AUTOSAR XML (schema 4-0-3)
package /ComponentTypes
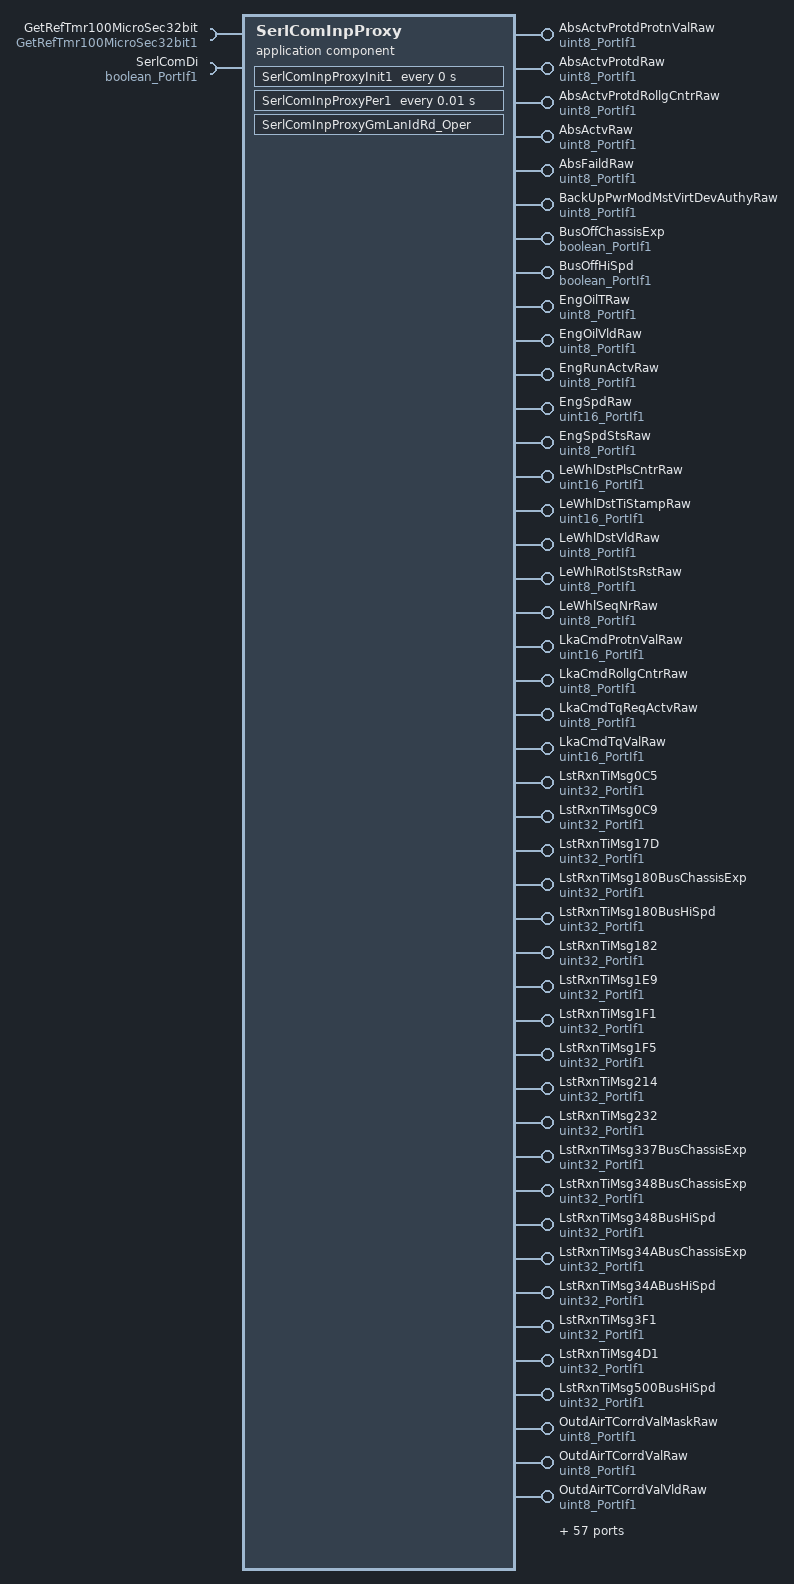
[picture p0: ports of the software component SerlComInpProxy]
  application sw component type SerlComInpProxy
    101 x provide port:
      AbsActvProtdProtnValRaw: nonqueued-sender-com-spec{data-element=Val, init-value=0}, provided-interface=uint8_PortIf1
      AbsActvProtdRaw: nonqueued-sender-com-spec{data-element=Val, init-value=0}, provided-interface=uint8_PortIf1
      AbsActvProtdRollgCntrRaw: nonqueued-sender-com-spec{data-element=Val, init-value=0}, provided-interface=uint8_PortIf1
      AbsActvRaw: nonqueued-sender-com-spec{data-element=Val, init-value=0}, provided-interface=uint8_PortIf1
      AbsFaildRaw: nonqueued-sender-com-spec{data-element=Val, init-value=0}, provided-interface=uint8_PortIf1
      BackUpPwrModMstVirtDevAuthyRaw: nonqueued-sender-com-spec{data-element=Val, init-value=0}, provided-interface=uint8_PortIf1
      BusOffChassisExp: nonqueued-sender-com-spec{data-element=Logl, init-value=0}, provided-interface=boolean_PortIf1
      BusOffHiSpd: nonqueued-sender-com-spec{data-element=Logl, init-value=0}, provided-interface=boolean_PortIf1
      EngOilTRaw: nonqueued-sender-com-spec{data-element=Val, init-value=0}, provided-interface=uint8_PortIf1
      EngOilVldRaw: nonqueued-sender-com-spec{data-element=Val, init-value=0}, provided-interface=uint8_PortIf1
      EngRunActvRaw: nonqueued-sender-com-spec{data-element=Val, init-value=0}, provided-interface=uint8_PortIf1
      EngSpdRaw: nonqueued-sender-com-spec{data-element=Val, init-value=0}, provided-interface=uint16_PortIf1
      EngSpdStsRaw: nonqueued-sender-com-spec{data-element=Val, init-value=0}, provided-interface=uint8_PortIf1
      LeWhlDstPlsCntrRaw: nonqueued-sender-com-spec{data-element=Val, init-value=0}, provided-interface=uint16_PortIf1
      LeWhlDstTiStampRaw: nonqueued-sender-com-spec{data-element=Val, init-value=0}, provided-interface=uint16_PortIf1
      LeWhlDstVldRaw: nonqueued-sender-com-spec{data-element=Val, init-value=0}, provided-interface=uint8_PortIf1
      LeWhlRotlStsRstRaw: nonqueued-sender-com-spec{data-element=Val, init-value=0}, provided-interface=uint8_PortIf1
      LeWhlSeqNrRaw: nonqueued-sender-com-spec{data-element=Val, init-value=0}, provided-interface=uint8_PortIf1
      LkaCmdProtnValRaw: nonqueued-sender-com-spec{data-element=Val, init-value=0}, provided-interface=uint16_PortIf1
      LkaCmdRollgCntrRaw: nonqueued-sender-com-spec{data-element=Val, init-value=0}, provided-interface=uint8_PortIf1
      LkaCmdTqReqActvRaw: nonqueued-sender-com-spec{data-element=Val, init-value=0}, provided-interface=uint8_PortIf1
      LkaCmdTqValRaw: nonqueued-sender-com-spec{data-element=Val, init-value=0}, provided-interface=uint16_PortIf1
      LstRxnTiMsg0C5: nonqueued-sender-com-spec{data-element=Val, init-value=0}, provided-interface=uint32_PortIf1
      LstRxnTiMsg0C9: nonqueued-sender-com-spec{data-element=Val, init-value=0}, provided-interface=uint32_PortIf1
      LstRxnTiMsg17D: nonqueued-sender-com-spec{data-element=Val, init-value=0}, provided-interface=uint32_PortIf1
      LstRxnTiMsg180BusChassisExp: nonqueued-sender-com-spec{data-element=Val, init-value=0}, provided-interface=uint32_PortIf1
      LstRxnTiMsg180BusHiSpd: nonqueued-sender-com-spec{data-element=Val, init-value=0}, provided-interface=uint32_PortIf1
      LstRxnTiMsg182: nonqueued-sender-com-spec{data-element=Val, init-value=0}, provided-interface=uint32_PortIf1
      LstRxnTiMsg1E9: nonqueued-sender-com-spec{data-element=Val, init-value=0}, provided-interface=uint32_PortIf1
      LstRxnTiMsg1F1: nonqueued-sender-com-spec{data-element=Val, init-value=0}, provided-interface=uint32_PortIf1
      LstRxnTiMsg1F5: nonqueued-sender-com-spec{data-element=Val, init-value=0}, provided-interface=uint32_PortIf1
      LstRxnTiMsg214: nonqueued-sender-com-spec{data-element=Val, init-value=0}, provided-interface=uint32_PortIf1
      LstRxnTiMsg232: nonqueued-sender-com-spec{data-element=Val, init-value=0}, provided-interface=uint32_PortIf1
      LstRxnTiMsg337BusChassisExp: nonqueued-sender-com-spec{data-element=Val, init-value=0}, provided-interface=uint32_PortIf1
      LstRxnTiMsg348BusChassisExp: nonqueued-sender-com-spec{data-element=Val, init-value=0}, provided-interface=uint32_PortIf1
      LstRxnTiMsg348BusHiSpd: nonqueued-sender-com-spec{data-element=Val, init-value=0}, provided-interface=uint32_PortIf1
      LstRxnTiMsg34ABusChassisExp: nonqueued-sender-com-spec{data-element=Val, init-value=0}, provided-interface=uint32_PortIf1
      LstRxnTiMsg34ABusHiSpd: nonqueued-sender-com-spec{data-element=Val, init-value=0}, provided-interface=uint32_PortIf1
      LstRxnTiMsg3F1: nonqueued-sender-com-spec{data-element=Val, init-value=0}, provided-interface=uint32_PortIf1
      LstRxnTiMsg4D1: nonqueued-sender-com-spec{data-element=Val, init-value=0}, provided-interface=uint32_PortIf1
      LstRxnTiMsg500BusHiSpd: nonqueued-sender-com-spec{data-element=Val, init-value=0}, provided-interface=uint32_PortIf1
      OutdAirTCorrdValMaskRaw: nonqueued-sender-com-spec{data-element=Val, init-value=0}, provided-interface=uint8_PortIf1
      OutdAirTCorrdValRaw: nonqueued-sender-com-spec{data-element=Val, init-value=0}, provided-interface=uint8_PortIf1
      OutdAirTCorrdValVldRaw: nonqueued-sender-com-spec{data-element=Val, init-value=0}, provided-interface=uint8_PortIf1
      PtCrkActvRaw: nonqueued-sender-com-spec{data-element=Val, init-value=0}, provided-interface=uint8_PortIf1
      RdntVehStabyEnhmtSysActvRaw: nonqueued-sender-com-spec{data-element=Val, init-value=0}, provided-interface=uint8_PortIf1
      RdntVehStabyEnhmtSysActvRollgCntrRaw: nonqueued-sender-com-spec{data-element=Val, init-value=0}, provided-interface=uint8_PortIf1
      RiWhlDstPlsCntrRaw: nonqueued-sender-com-spec{data-element=Val, init-value=0}, provided-interface=uint16_PortIf1
      RiWhlDstTiStampRaw: nonqueued-sender-com-spec{data-element=Val, init-value=0}, provided-interface=uint16_PortIf1
      RiWhlDstVldRaw: nonqueued-sender-com-spec{data-element=Val, init-value=0}, provided-interface=uint8_PortIf1
      RiWhlRotlStsRstRaw: nonqueued-sender-com-spec{data-element=Val, init-value=0}, provided-interface=uint8_PortIf1
      RiWhlSeqNrRaw: nonqueued-sender-com-spec{data-element=Val, init-value=0}, provided-interface=uint8_PortIf1
      SerlComInpProxyGmLanIdRd: server-com-spec{operation=Oper, queue-length=1}, provided-interface=SerlComInpProxyGmLanIdRd1
      ShiftLvrPosnRaw: nonqueued-sender-com-spec{data-element=Val, init-value=0}, provided-interface=uint8_PortIf1
      ShiftLvrPosnVldRaw: nonqueued-sender-com-spec{data-element=Val, init-value=0}, provided-interface=uint8_PortIf1
      SteerSysPrfmncModReqRaw: nonqueued-sender-com-spec{data-element=Val, init-value=0}, provided-interface=uint8_PortIf1
      SteerWhlAgReqActvRaw: nonqueued-sender-com-spec{data-element=Val, init-value=0}, provided-interface=uint8_PortIf1
      SteerWhlAgReqActvVldRaw: nonqueued-sender-com-spec{data-element=Val, init-value=0}, provided-interface=uint8_PortIf1
      SteerWhlAgReqProtnValRaw: nonqueued-sender-com-spec{data-element=Val, init-value=0}, provided-interface=uint32_PortIf1
      SteerWhlAgReqRollgCntrRaw: nonqueued-sender-com-spec{data-element=Val, init-value=0}, provided-interface=uint8_PortIf1
      SteerWhlAgReqTarAgRaw: nonqueued-sender-com-spec{data-element=Val, init-value=0}, provided-interface=uint16_PortIf1
      SteerWhlFbReqActvProtnValRaw: nonqueued-sender-com-spec{data-element=Val, init-value=0}, provided-interface=uint8_PortIf1
      SteerWhlFbReqActvRaw: nonqueued-sender-com-spec{data-element=Val, init-value=0}, provided-interface=uint8_PortIf1
      SteerWhlFbReqActvRollgCntrRaw: nonqueued-sender-com-spec{data-element=Val, init-value=0}, provided-interface=uint8_PortIf1
      SysBackUpPwrModEnaRaw: nonqueued-sender-com-spec{data-element=Val, init-value=0}, provided-interface=uint8_PortIf1
      SysBackUpPwrModRaw: nonqueued-sender-com-spec{data-element=Val, init-value=0}, provided-interface=uint8_PortIf1
      SysPwrModRaw: nonqueued-sender-com-spec{data-element=Val, init-value=0}, provided-interface=uint8_PortIf1
      TqOvrlAlvRollgCntrRaw: nonqueued-sender-com-spec{data-element=Val, init-value=0}, provided-interface=uint8_PortIf1
      TqOvrlCmdChksRaw: nonqueued-sender-com-spec{data-element=Val, init-value=0}, provided-interface=uint16_PortIf1
      TqOvrlDeltaTqCmdActvRaw: nonqueued-sender-com-spec{data-element=Val, init-value=0}, provided-interface=uint8_PortIf1
      TqOvrlDeltaTqCmdValRaw: nonqueued-sender-com-spec{data-element=Val, init-value=0}, provided-interface=uint16_PortIf1
      TracCtrlSysActvRaw: nonqueued-sender-com-spec{data-element=Val, init-value=0}, provided-interface=uint8_PortIf1
      TracCtrlSysEnaRaw: nonqueued-sender-com-spec{data-element=Val, init-value=0}, provided-interface=uint8_PortIf1
      VehDynCtrlSysStRaw: nonqueued-sender-com-spec{data-element=Val, init-value=0}, provided-interface=uint8_PortIf1
      VehDynOverUnderSteerVldRaw: nonqueued-sender-com-spec{data-element=Val, init-value=0}, provided-interface=uint8_PortIf1
      VehDynYawRateRaw: nonqueued-sender-com-spec{data-element=Val, init-value=0}, provided-interface=uint16_PortIf1
      VehDynYawRateVldRaw: nonqueued-sender-com-spec{data-element=Val, init-value=0}, provided-interface=uint8_PortIf1
      VehStabyEnhmtActvRaw: nonqueued-sender-com-spec{data-element=Val, init-value=0}, provided-interface=uint8_PortIf1
      VehStabyEnhmtLatARaw: nonqueued-sender-com-spec{data-element=Val, init-value=0}, provided-interface=uint16_PortIf1
      VehStabyEnhmtLatAVldRaw: nonqueued-sender-com-spec{data-element=Val, init-value=0}, provided-interface=uint8_PortIf1
      VehStabyEnhmtLgtALoReslRaw: nonqueued-sender-com-spec{data-element=Val, init-value=0}, provided-interface=uint16_PortIf1
      VehStabyEnhmtLgtALoReslVldRaw: nonqueued-sender-com-spec{data-element=Val, init-value=0}, provided-interface=uint8_PortIf1
      VehStabyEnhmtStsRaw: nonqueued-sender-com-spec{data-element=Val, init-value=0}, provided-interface=uint8_PortIf1
      WhlGndVelLeDrvnRawBusChassisExp: nonqueued-sender-com-spec{data-element=Val, init-value=0}, provided-interface=uint16_PortIf1
      WhlGndVelLeDrvnRawBusHiSpd: nonqueued-sender-com-spec{data-element=Val, init-value=0}, provided-interface=uint16_PortIf1
      WhlGndVelLeDrvnVldRawBusChassisExp: nonqueued-sender-com-spec{data-element=Val, init-value=0}, provided-interface=uint8_PortIf1
      WhlGndVelLeDrvnVldRawBusHiSpd: nonqueued-sender-com-spec{data-element=Val, init-value=0}, provided-interface=uint8_PortIf1
      WhlGndVelLeNonDrvnRawBusChassisExp: nonqueued-sender-com-spec{data-element=Val, init-value=0}, provided-interface=uint16_PortIf1
      WhlGndVelLeNonDrvnRawBusHiSpd: nonqueued-sender-com-spec{data-element=Val, init-value=0}, provided-interface=uint16_PortIf1
      WhlGndVelLeNonDrvnVldRawBusChassisExp: nonqueued-sender-com-spec{data-element=Val, init-value=0}, provided-interface=uint8_PortIf1
      WhlGndVelLeNonDrvnVldRawBusHiSpd: nonqueued-sender-com-spec{data-element=Val, init-value=0}, provided-interface=uint8_PortIf1
      WhlGndVelRiDrvnRawBusChassisExp: nonqueued-sender-com-spec{data-element=Val, init-value=0}, provided-interface=uint16_PortIf1
      WhlGndVelRiDrvnRawBusHiSpd: nonqueued-sender-com-spec{data-element=Val, init-value=0}, provided-interface=uint16_PortIf1
      WhlGndVelRiDrvnVldRawBusChassisExp: nonqueued-sender-com-spec{data-element=Val, init-value=0}, provided-interface=uint8_PortIf1
      WhlGndVelRiDrvnVldRawBusHiSpd: nonqueued-sender-com-spec{data-element=Val, init-value=0}, provided-interface=uint8_PortIf1
      WhlGndVelRiNonDrvnRawBusChassisExp: nonqueued-sender-com-spec{data-element=Val, init-value=0}, provided-interface=uint16_PortIf1
      WhlGndVelRiNonDrvnRawBusHiSpd: nonqueued-sender-com-spec{data-element=Val, init-value=0}, provided-interface=uint16_PortIf1
      WhlGndVelRiNonDrvnVldRawBusChassisExp: nonqueued-sender-com-spec{data-element=Val, init-value=0}, provided-interface=uint8_PortIf1
      WhlGndVelRiNonDrvnVldRawBusHiSpd: nonqueued-sender-com-spec{data-element=Val, init-value=0}, provided-interface=uint8_PortIf1
      WhlPlsPerRevRaw: nonqueued-sender-com-spec{data-element=Val, init-value=0}, provided-interface=uint8_PortIf1
      WhlRotlStsTiStampReslRaw: nonqueued-sender-com-spec{data-element=Val, init-value=0}, provided-interface=uint16_PortIf1
    require port GetRefTmr100MicroSec32bit: required-interface=GetRefTmr100MicroSec32bit1
    require port SerlComDi: nonqueued-receiver-com-spec{data-element=Logl, filter=data-filter-type=ALWAYS, init-value=0}, required-interface=boolean_PortIf1
    behavior SerlComInpProxy_InternalBehavior
      operation invoked event OIT_SerlComInpProxyGmLanIdRd_Oper_SerlComInpProxyGmLanIdRd_Oper: start-on-event=SerlComInpProxyGmLanIdRd_Oper, operation=SerlComInpProxyGmLanIdRd.Oper
      timing event SerlComInpProxy_InitEvent: start-on-event=SerlComInpProxyInit1, period=0
      timing event TMT_SerlComInpProxyPer1: start-on-event=SerlComInpProxyPer1, period=0.01
      runnable SerlComInpProxyGmLanIdRd_Oper
      runnable SerlComInpProxyInit1
      runnable SerlComInpProxyPer1
        data-receive-point-by-arguments:
          access REC_SerlComDi_Logl: accessed-variable=SerlComDi.Logl
        data-send-points:
          100 x access:
            SEND_AbsActvProtdProtnValRaw_Val: accessed-variable=AbsActvProtdProtnValRaw.Val
            SEND_AbsActvProtdRaw_Val: accessed-variable=AbsActvProtdRaw.Val
            SEND_AbsActvProtdRollgCntrRaw_Val: accessed-variable=AbsActvProtdRollgCntrRaw.Val
            SEND_AbsActvRaw_Val: accessed-variable=AbsActvRaw.Val
            SEND_AbsFaildRaw_Val: accessed-variable=AbsFaildRaw.Val
            SEND_BackUpPwrModMstVirtDevAuthy_Val: accessed-variable=BackUpPwrModMstVirtDevAuthyRaw.Val
            SEND_BusOffChassisExp_Logl: accessed-variable=BusOffChassisExp.Logl
            SEND_BusOffHiSpd_Logl: accessed-variable=BusOffHiSpd.Logl
            SEND_ChassisExpWhlGndVelLeDrvn_Val: accessed-variable=WhlGndVelLeDrvnRawBusChassisExp.Val
            SEND_ChassisExpWhlGndVelLeDrvnVld_Val: accessed-variable=WhlGndVelLeDrvnVldRawBusChassisExp.Val
            SEND_ChassisExpWhlGndVelLeNonDrvn_Val: accessed-variable=WhlGndVelLeNonDrvnRawBusChassisExp.Val
            SEND_ChassisExpWhlGndVelLeNonDrvnVld_Val: accessed-variable=WhlGndVelLeNonDrvnVldRawBusChassisExp.Val
            SEND_ChassisExpWhlGndVelRiDrvn_Val: accessed-variable=WhlGndVelRiDrvnRawBusChassisExp.Val
            SEND_ChassisExpWhlGndVelRiDrvnVld_Val: accessed-variable=WhlGndVelRiDrvnVldRawBusChassisExp.Val
            SEND_ChassisExpWhlGndVelRiNonDrvn_Val: accessed-variable=WhlGndVelRiNonDrvnRawBusChassisExp.Val
            SEND_ChassisExpWhlGndVelRiNonDrvnVld_Val: accessed-variable=WhlGndVelRiNonDrvnVldRawBusChassisExp.Val
            SEND_EngCooltT_Val: accessed-variable=EngOilTRaw.Val
            SEND_EngCooltVld_Val: accessed-variable=EngOilVldRaw.Val
            SEND_EngRunActv_Val: accessed-variable=EngRunActvRaw.Val
            SEND_EngSpd_Val: accessed-variable=EngSpdRaw.Val
            SEND_EngSpdSts_Val: accessed-variable=EngSpdStsRaw.Val
            SEND_HiSpdWhlGndVelLeDrvn_Val: accessed-variable=WhlGndVelLeDrvnRawBusHiSpd.Val
            SEND_HiSpdWhlGndVelLeDrvnVld_Val: accessed-variable=WhlGndVelLeDrvnVldRawBusHiSpd.Val
            SEND_HiSpdWhlGndVelLeNonDrvn_Val: accessed-variable=WhlGndVelLeNonDrvnRawBusHiSpd.Val
            SEND_HiSpdWhlGndVelLeNonDrvnVld_Val: accessed-variable=WhlGndVelLeNonDrvnVldRawBusHiSpd.Val
            SEND_HiSpdWhlGndVelRiDrvn_Val: accessed-variable=WhlGndVelRiDrvnRawBusHiSpd.Val
            SEND_HiSpdWhlGndVelRiDrvnVld_Val: accessed-variable=WhlGndVelRiDrvnVldRawBusHiSpd.Val
            SEND_HiSpdWhlGndVelRiNonDrvn_Val: accessed-variable=WhlGndVelRiNonDrvnRawBusHiSpd.Val
            SEND_HiSpdWhlGndVelRiNonDrvnVld_Val: accessed-variable=WhlGndVelRiNonDrvnVldRawBusHiSpd.Val
            SEND_LeWhlDstPlsCntrRaw_Val: accessed-variable=LeWhlDstPlsCntrRaw.Val
            SEND_LeWhlDstTiStampRaw_Val: accessed-variable=LeWhlDstTiStampRaw.Val
            SEND_LeWhlDstVldRaw_Val: accessed-variable=LeWhlDstVldRaw.Val
            SEND_LeWhlRotlStsRstRaw_Val: accessed-variable=LeWhlRotlStsRstRaw.Val
            SEND_LeWhlSeqNrRaw_Val: accessed-variable=LeWhlSeqNrRaw.Val
            SEND_LkaCmdProtnValRaw_Val: accessed-variable=LkaCmdProtnValRaw.Val
            SEND_LkaCmdRollgCntrRaw_Val: accessed-variable=LkaCmdRollgCntrRaw.Val
            SEND_LkaCmdTqReqActvRaw_Val: accessed-variable=LkaCmdTqReqActvRaw.Val
            SEND_LkaCmdTqValRaw_Val: accessed-variable=LkaCmdTqValRaw.Val
            SEND_LstRxnTiMsg0C5BusHiSpd_Val: accessed-variable=LstRxnTiMsg0C5.Val
            SEND_LstRxnTiMsg17D_Val: accessed-variable=LstRxnTiMsg17D.Val
            SEND_LstRxnTiMsg180BusChassisExp_Val: accessed-variable=LstRxnTiMsg180BusChassisExp.Val
            SEND_LstRxnTiMsg180BusHiSpd_Val: accessed-variable=LstRxnTiMsg180BusHiSpd.Val
            SEND_LstRxnTiMsg182_Val: accessed-variable=LstRxnTiMsg182.Val
            SEND_LstRxnTiMsg1E9_Val: accessed-variable=LstRxnTiMsg1E9.Val
            SEND_LstRxnTiMsg1F5_Val: accessed-variable=LstRxnTiMsg1F5.Val
            SEND_LstRxnTiMsg214_Val: accessed-variable=LstRxnTiMsg214.Val
            SEND_LstRxnTiMsg232_Val: accessed-variable=LstRxnTiMsg232.Val
            SEND_LstRxnTiMsg337BusChassisExp_Val: accessed-variable=LstRxnTiMsg337BusChassisExp.Val
            SEND_LstRxnTiMsg500BusHiSpd_Val: accessed-variable=LstRxnTiMsg500BusHiSpd.Val
            SEND_Msg0C9HSLstRxnTi_Val: accessed-variable=LstRxnTiMsg0C9.Val
            SEND_Msg1F1HSLstRxnTi_Val: accessed-variable=LstRxnTiMsg1F1.Val
            SEND_Msg348CELstRxnTi_Val: accessed-variable=LstRxnTiMsg348BusChassisExp.Val
            SEND_Msg348HSLstRxnTi_Val: accessed-variable=LstRxnTiMsg348BusHiSpd.Val
            SEND_Msg34ACELstRxnTi_Val: accessed-variable=LstRxnTiMsg34ABusChassisExp.Val
            SEND_Msg34AHSLstRxnTi_Val: accessed-variable=LstRxnTiMsg34ABusHiSpd.Val
            SEND_Msg3F1HSLstRxnTi_Val: accessed-variable=LstRxnTiMsg3F1.Val
            SEND_Msg4C1HSLstRxnTi_Val: accessed-variable=LstRxnTiMsg4D1.Val
            SEND_OutdAirTCorrdVal_Val: accessed-variable=OutdAirTCorrdValRaw.Val
            SEND_OutdAirTCorrdValMask_Val: accessed-variable=OutdAirTCorrdValMaskRaw.Val
            SEND_OutdAirTCorrdValVld_Val: accessed-variable=OutdAirTCorrdValVldRaw.Val
            SEND_PtCrkActv_Val: accessed-variable=PtCrkActvRaw.Val
            SEND_RdntVehStabyEnhmtSysActvRaw_Val: accessed-variable=RdntVehStabyEnhmtSysActvRaw.Val
            SEND_RdntVehStabyEnhmtSysActvRollgCntrRaw_Val: accessed-variable=RdntVehStabyEnhmtSysActvRollgCntrRaw.Val
            SEND_RiWhlDstPlsCntrRaw_Val: accessed-variable=RiWhlDstPlsCntrRaw.Val
            SEND_RiWhlDstTiStampRaw_Val: accessed-variable=RiWhlDstTiStampRaw.Val
            SEND_RiWhlDstVldRaw_Val: accessed-variable=RiWhlDstVldRaw.Val
            SEND_RiWhlRotlStsRstRaw_Val: accessed-variable=RiWhlRotlStsRstRaw.Val
            SEND_RiWhlSeqNrRaw_Val: accessed-variable=RiWhlSeqNrRaw.Val
            SEND_ShiftLvrPosnRaw_Val: accessed-variable=ShiftLvrPosnRaw.Val
            SEND_ShiftLvrPosnVldRaw_Val: accessed-variable=ShiftLvrPosnVldRaw.Val
            SEND_SteerSysPrfmncModReqRaw_Val: accessed-variable=SteerSysPrfmncModReqRaw.Val
            SEND_SteerWhlAgReqActvRaw_Val: accessed-variable=SteerWhlAgReqActvRaw.Val
            SEND_SteerWhlAgReqActvVldRaw_Val: accessed-variable=SteerWhlAgReqActvVldRaw.Val
            SEND_SteerWhlAgReqProtnValRaw_Val: accessed-variable=SteerWhlAgReqProtnValRaw.Val
            SEND_SteerWhlAgReqRollgCntrRaw_Val: accessed-variable=SteerWhlAgReqRollgCntrRaw.Val
            SEND_SteerWhlAgReqTarAgRaw_Val: accessed-variable=SteerWhlAgReqTarAgRaw.Val
            SEND_SteerWhlFdReqActvProtnValRaw_Val: accessed-variable=SteerWhlFbReqActvProtnValRaw.Val
            SEND_SteerWhlFdReqActvRaw_Val: accessed-variable=SteerWhlFbReqActvRaw.Val
            SEND_SteerWhlFdReqActvRollgCntrRaw_Val: accessed-variable=SteerWhlFbReqActvRollgCntrRaw.Val
            SEND_SysBackUpPwrMod_Val: accessed-variable=SysBackUpPwrModRaw.Val
            SEND_SysBackUpPwrModEna_Val: accessed-variable=SysBackUpPwrModEnaRaw.Val
            SEND_SysPwrMod_Val: accessed-variable=SysPwrModRaw.Val
            SEND_TqOvrlAlvRollgCntrRaw_Val: accessed-variable=TqOvrlAlvRollgCntrRaw.Val
            SEND_TqOvrlCmdChksRaw_Val: accessed-variable=TqOvrlCmdChksRaw.Val
            SEND_TqOvrlDeltaTqCmdActvRaw_Val: accessed-variable=TqOvrlDeltaTqCmdActvRaw.Val
            SEND_TqOvrlDeltaTqCmdValRaw_Val: accessed-variable=TqOvrlDeltaTqCmdValRaw.Val
            SEND_TracCtrlSysActvRaw_Val: accessed-variable=TracCtrlSysActvRaw.Val
            SEND_TracCtrlSysEnaRaw_Val: accessed-variable=TracCtrlSysEnaRaw.Val
            SEND_VehDynCtrlSysStRaw_Val: accessed-variable=VehDynCtrlSysStRaw.Val
            SEND_VehDynOverUnderSteerVldRaw_Val: accessed-variable=VehDynOverUnderSteerVldRaw.Val
            SEND_VehDynYawRateRaw_Val: accessed-variable=VehDynYawRateRaw.Val
            SEND_VehDynYawRateVldRaw_Val: accessed-variable=VehDynYawRateVldRaw.Val
            SEND_VehStabyEnhmtActvRaw_Val: accessed-variable=VehStabyEnhmtActvRaw.Val
            SEND_VehStabyEnhmtLatARaw_Val: accessed-variable=VehStabyEnhmtLatARaw.Val
            SEND_VehStabyEnhmtLatAVldRaw_Val: accessed-variable=VehStabyEnhmtLatAVldRaw.Val
            SEND_VehStabyEnhmtLgtALoReslRaw_Val: accessed-variable=VehStabyEnhmtLgtALoReslRaw.Val
            SEND_VehStabyEnhmtLgtALoReslVldRaw_Val: accessed-variable=VehStabyEnhmtLgtALoReslVldRaw.Val
            SEND_VehStabyEnhmtStsRaw_Val: accessed-variable=VehStabyEnhmtStsRaw.Val
            SEND_WhlPlsPerRevRaw_Val: accessed-variable=WhlPlsPerRevRaw.Val
            SEND_WhlRotlStsTiStampReslRaw_Val: accessed-variable=WhlRotlStsTiStampReslRaw.Val
        sync call SC_GetRefTmr100MicroSec32bit_Oper: operation=GetRefTmr100MicroSec32bit.Oper, timeout=0
  swc implementation SerlComInpProxy_Implementation: behavior=SerlComInpProxy_InternalBehavior
    code-descriptors:
      code Default: artifact-descriptors=autosar-engineering-object={short-label=Default, category=SWSRC}
